# RZN2H register map
Vendor: Renesas Electronics Corporation; Series: RZN; File version: 1.00.00
CPU: other r0p0, little endian, MPU, no FPU, VTOR, 4 interrupt priority bits, 624 interrupts
Registers are 32-bit, read-write, reset 0x0 unless marked. A register's access mark holds for its fields unless they carry their own. Offsets are from the block's base; [hi:lo] are bit positions; {n}, {i} and the like mark numbered series; 'fields as' and 'values as' point back to an identical list; <NAME> marks a mode.

## SDHI0 — SD/MMC Host Interface
Base 0x92080000
Same registers: SDHI1 0x92090000
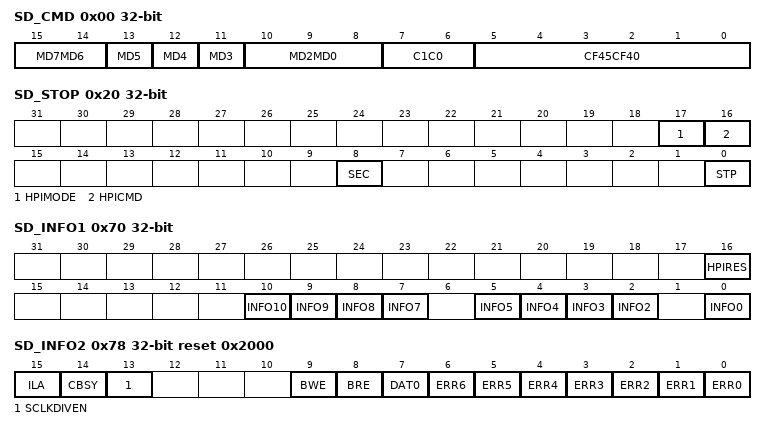
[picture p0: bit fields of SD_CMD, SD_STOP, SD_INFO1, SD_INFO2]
0x00 SD_CMD — Command Type Register
  [15:14] MD7MD6 — Multiple Block Transfer Mode (enabled at multiple block transfer)
    0=CMD12 is automatically issued at multiple block transfer; 1=CMD12 is not automatically issued at multiple block transfer; 2=Setting prohibited; 3=Setting prohibited
  [13] MD5 — Single/Multiple Block Transfer (enabled when the command with data is handled)
    0=Single block transfer; 1=Multi block transfer
  [12] MD4 — Write/Read Mode (enabled when the command with data is handled)
    0=Write (SD/MMC host interface -> SD card); 1=Read (SD/MMC host interface <- SD card)
  [11] MD3 — Data Mode (Command Type)
    0=Command without data transfer (bc, bcr, ac); 1=Command with data transfer (adtc)
  [10:8] MD2MD0 — Mode/Response Type
    0=Normal mode The response type and the transfer mode are selected by SD_CMD[7:0], and the SD_CMD[15:11] setting is disabled; 1=Setting prohibited; 2=Setting prohibited; 3=Extended mode/No response; 4=Extended mode/R1, R5, R6, or R7 response from the SD card; 5=Extended mode/R1b response from the SD card; 6=Extended mode/R2 response from the SD card; 7=Extended mode/R3 or R4 response from the SD card
  [7:6] C1C0
    0=CMD; 1=ACMD; 2=Setting prohibited
  [5:0] CF45CF40 — Command Index
0x10 SD_ARG — Command Argument Register
0x18 SD_ARG1 — Command Argument Register 1
0x20 SD_STOP — Data Stop Register
  [17] HPIMODE — HPI Mode Enable
    0=Disables HPI mode; 1=Enables HPI mode
  [16] HPICMD — HPI Command Issue
  [8] SEC — Block Count Enable
    0=Disables SD_SECCNT setting value; 1=Enables SD_SECCNT setting value
  [0] STP — Stop
0x28 SD_SECCNT — Block Count Register
  [31:0] CNT31CNT0 — Number of Transfer Blocks
0x30 SD_RSP10L ro — SD Card Response 10L Register
  [31:0] R39R8 — Hold the response from the SD card
0x38 SD_RSP1 ro — SD Card Response 1 Register
  [15:0] R39R24 — Hold the response from the SD card
0x38 SD_RSP10H ro (alternate view of SD_RSP1) — SD Card Response 10H Register
  [31:0] R71R40 — Hold the response from the SD card
0x40 SD_RSP32 ro — SD Card Response 32 Register
  [31:0] R71R40
0x48 SD_RSP3 ro — SD Card Response 3 Register
  [15:0] R71R56
0x50 SD_RSP54L ro — SD Card Response 54L Register
  [31:0] R103R72 — Hold the response from the SD card
0x58 SD_RSP5 ro — SD Card Response 5 Register
  [15:0] R103R88
0x58 SD_RSP54H ro (alternate view of SD_RSP5) — SD Card Response 54H Register
  [23:0] R127R104 — Hold the response from the SD card
0x60 SD_RSP76 ro — SD Card Response 76 Register
  [23:0] R127R104
0x68 SD_RSP7 ro — SD Card Response 7 Register
  [7:0] R127R120
0x70 SD_INFO1 (reset mask 0xFFFFFB5F) — SD Card Interrupt Flag Register 1
  [16] HPIRES — Response Reception Completion
  [10] INFO10 ro
    0=SDDAT3 is set to 0; 1=SDDAT3 is set to 1
  [9] INFO9 — SDDAT3 Card Insertion
  [8] INFO8 — SDDAT3 Card Removal
  [7] INFO7 ro — Write Protect
    0=ISDWP is set to 1; 1=ISDWP is set to 0
  [5] INFO5 ro — Indicates the ISDCD state.
    0=Indicates that Mcycle has elapsed with ISDCD held at 1; 1=Indicates that Mcycle has elapsed with ISDCD held at 0
  [4] INFO4 — ISDCD Card Insertion
  [3] INFO3 — ISDCD Card Removal
  [2] INFO2 — Access End
  [0] INFO0 — Response End
0x78 SD_INFO2 reset 0x2000 (reset mask 0xFFFFFF7F) — SD Card Interrupt Flag Register 2
  [15] ILA — Illegal Access Error
  [14] CBSY ro — Command Type Register Busy
    0=A command sequence has been completed; 1=A command sequence is being executed
  [13] SCLKDIVEN ro — When a command sequence is started by writing to SD_CMD, the CBSY bit is set to 1 and, at the same time, the SCLKDIVEN bit is set to 0. The SCLKDIVEN bit is set to 1 after 8 cycles of SDCLK have elapsed after setting of the CBSY bit to 0 due to completion of the command sequence.
    0=The SD bus (CMD, DAT) is busy. Do not attempt to write to the SD_CLK_CTRL register.; 1=The SD bus (CMD, DAT) is not busy
  [9] BWE — SD_BUF Write Enable
    0=Data cannot be written in SD_BUF0; 1=Data can be written in SD_BUF0
  [8] BRE — SD_BUF Read Enable
    0=Data cannot be read from SD_BUF0; 1=Data can be read from SD_BUF0
  [7] DAT0 ro — SDDAT0
    0=SDDAT0 is set to 0; 1=SDDAT0 is set to 1
  [6] ERR6 — Response Timeout
  [5] ERR5 — SD_BUF Illegal Read Access
  [4] ERR4 — SD_BUF Illegal Write Access
  [3] ERR3 — Data Timeout (except response timeout)
  [2] ERR2 — END Error
  [1] ERR1 — CRC Error
  [0] ERR0 — CMD Error
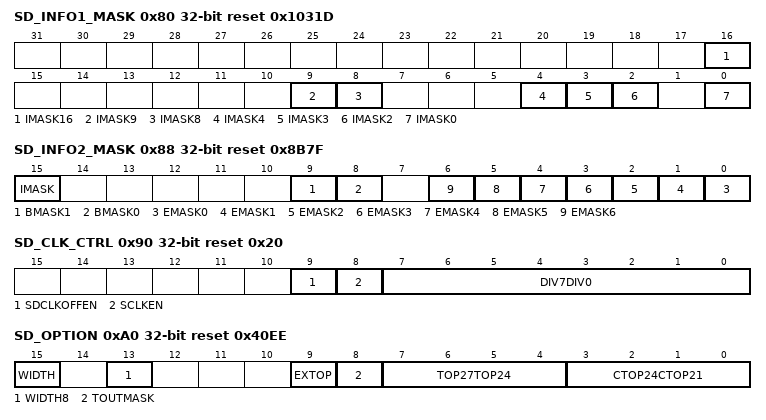
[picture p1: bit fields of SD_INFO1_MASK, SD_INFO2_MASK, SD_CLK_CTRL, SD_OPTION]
0x80 SD_INFO1_MASK reset 0x1031D — SD_INFO1 Interrupt Mask Register
  [16] IMASK16, [9] IMASK9, [8] IMASK8, [4] IMASK4, [3] IMASK3, [2] IMASK2, [0] IMASK0
0x88 SD_INFO2_MASK reset 0x8B7F — SD_INFO2 Interrupt Mask Register
  [15] IMASK, [9] BMASK1, [8] BMASK0, [n] EMASK{n} (n=0..6)
0x90 SD_CLK_CTRL reset 0x20 — SD Clock Control Register
  [9] SDCLKOFFEN — SD Clock (SDCLK) Output Automatic Control Enable
    0=Automatic control for SD clock (SDCLK) output is disabled; 1=Automatic control for SD clock (SDCLK) output is enabled
  [8] SCLKEN
    0=SD clock (SDCLK) output is disabled. The SDCLK signal is fixed 0.; 1=SD clock (SDCLK) output is enabled
  [7:0] DIV7DIV0 — SD Clock (SDCLK)
    128=PCLKAM/512; 64=PCLKAM/256; 32=PCLKAM/128; 16=PCLKAM/64; 8=PCLKAM/32; 4=PCLKAM/16; 2=PCLKAM/8; 1=PCLKAM/4; 0=PCLKAM/2; 255=PCLKAM; other=Others (Setting prohibited)
0x98 SD_SIZE reset 0x200 — Transfer Data Length Register
  [9:0] LEN9LEN0 — Transfer Data Size
0xA0 SD_OPTION reset 0x40EE — SD Card Access Control Option Register
  [15] WIDTH — Bus width
  [13] WIDTH8 — Bus width
  [9] EXTOP
    0=The TOP27TOP24[3:0] bits specify the timeout count from 210 SDCLK to 224 SDCLK; 1=The TOP27TOP24[3:0] bits specify the timeout count from 211 SDCLK to 225 SDCLK
  [8] TOUTMASK — Timeout Mask
    0=Enables timeout; 1=Disables timeout (The ERR6 and ERR3 bits in SD_INFO2 and the E6 to E0 bits in SD_ERR_STS2 are not set.)
  [7:4] TOP27TOP24
  [3:0] CTOP24CTOP21 — Card Detect Time Counter
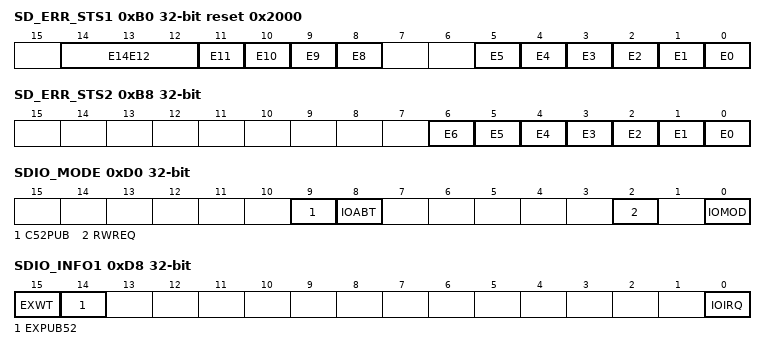
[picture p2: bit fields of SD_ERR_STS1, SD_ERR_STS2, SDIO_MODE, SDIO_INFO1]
0xB0 SD_ERR_STS1 ro reset 0x2000 — SD Error Status Register 1
  [14:12] E14E12
  [11] E11
  [10] E10
  [9] E9 — Set to 1 when a CRC error occurs in the response to a command issued within a command sequence.
  [8] E8
  [5] E5
  [4] E4
  [3] E3 — Set to 1 when an error occurs in the response length to a command issued within a command sequence.
  [2] E2
  [1] E1 — Set to 1 when an error occurs in the command index of the response to a command issued within a command sequence.
  [0] E0
0xB8 SD_ERR_STS2 ro — SD Error Status Register 2
  [6] E6
  [5] E5
  [4] E4 — Set to 1 when read data is not received even after Ncycle has elapsed after the command has been read.
  [3] E3 — Set to 1 when the interface remains in a busy state for at least Ncycle after CMD12 has been issued within a command sequence.
  [2] E2 — Set to 1 when the interface remains in a busy state for at least Ncycle after R1b response.
  [1] E1 — Set to 1 when the response to a command issued within a command sequence is not received even after 640 cycles of SDCLK have elapsed.
  [0] E0
0xC0 SD_BUF0H reset not defined — SD Buffer Read/Write H Register
0xC4 SD_BUF0L reset not defined — SD Buffer Read/Write L Register
0xD0 SDIO_MODE — SDIO Mode Control Register
  [9] C52PUB — SDIO None Abort
  [8] IOABT — SDIO Abort
  [2] RWREQ — Read Wait Request
  [0] IOMOD — SDIO Mode
    0=Disables the SD/MMC host interface to receive SDIO interrupts from the SDIO card; 1=Enables the SD/MMC host interface to receive SDIO interrupts from the SDIO card
0xD8 SDIO_INFO1 — SDIO Interrupt Flag Register
  [15] EXWT — [Setting condition]
  [14] EXPUB52 — [Setting conditions]
  [0] IOIRQ — [Setting condition]
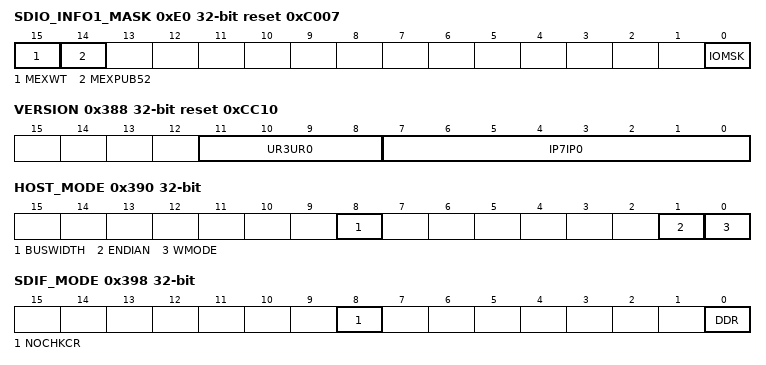
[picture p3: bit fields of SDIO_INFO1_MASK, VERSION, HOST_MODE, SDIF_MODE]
0xE0 SDIO_INFO1_MASK reset 0xC007 — SDIO_INFO1 Interrupt Mask Register
  [15] MEXWT, [14] MEXPUB52, [0] IOMSK
0x360 CC_EXT_MODE reset 0x1010 — DMA Mode Enable Register
  [1] DMASDRW — SD_BUF Read/Write DMA Transfer
    0=The SD_BUF read/write DMA transfer is disabled; 1=The SD_BUF read/write DMA transfer is enabled
0x380 SOFT_RST reset 0x7 — Software Reset Register
  [0] SDRST
    0=Reset; 1=Reset released
0x388 VERSION ro reset 0xCC10
  [11:8] UR3UR0, [7:0] IP7IP0
0x390 HOST_MODE — Host Interface Mode Setting Register
  [8] BUSWIDTH — Width for Access to SD_BUF
    0=16-bit access; 1=32-bit access
  [1] ENDIAN
  [0] WMODE — Width for Access to SD_BUF
    0=64-bit access; 1=16-bit or 32-bit access
0x398 SDIF_MODE — SD Interface Mode Setting Register
  [8] NOCHKCR — CRC Check Mask (test command for MMC supported)
    0=Enables the CRC check; 1=Disables the CRC check (the CRC16 value is ignored at read, and the CRC status is not detected at write)
  [0] DDR — DDR Mode Select
    0=Normal mode (default, high speed, or SDR); 1=DDR mode
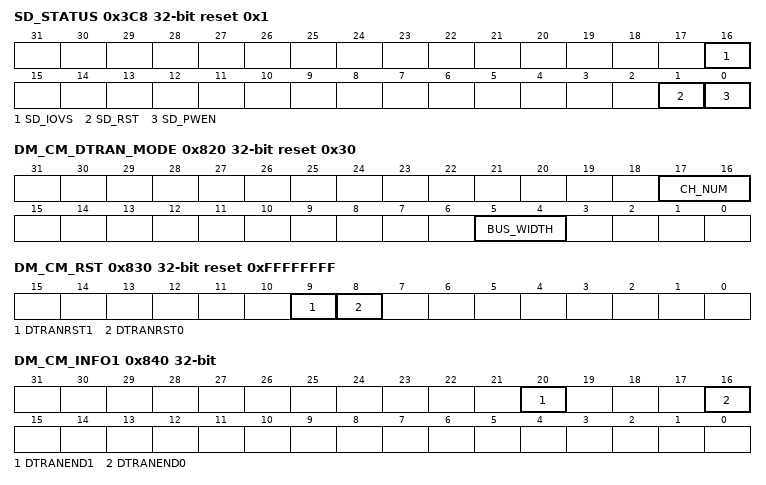
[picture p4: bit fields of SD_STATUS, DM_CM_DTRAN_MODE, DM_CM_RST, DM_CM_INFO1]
0x3C8 SD_STATUS reset 0x1
  [16] SD_IOVS
    0=The output value on the SDm_IOVS pin is 0; 1=The output value on the SDm_IOVS pin is 1
  [1] SD_RST
    0=The output value on the SD0_RST# pin is 0; 1=The output value on the SD0_RST# pin is 1
  [0] SD_PWEN
    0=The output value on the SDm_PWEN pin is 0; 1=The output value on the SDm_PWEN pin is 1
0x820 DM_CM_DTRAN_MODE reset 0x30 — DMAC Transfer Mode Register
  [17:16] CH_NUM
    0=SD downstream; 1=SD upstream; other=Others (Setting prohibited)
  [5:4] BUS_WIDTH
    3=64-bit; other=Others (Setting prohibited)
0x828 DM_CM_DTRAN_CTRL — DMAC Transfer Control Register
  [0] DM_START — DMAC Start
0x830 DM_CM_RST reset 0xFFFFFFFF — DMAC Reset Register
  [9] DTRANRST1
    0=Reset; 1=Reset released
  [8] DTRANRST0
    0=Reset; 1=Reset released
0x840 DM_CM_INFO1 — DMAC Interrupt Register 1
  [20] DTRANEND1 — DMAC Channel 1 Transfer End
  [16] DTRANEND0 — DMAC Channel 0 Transfer End
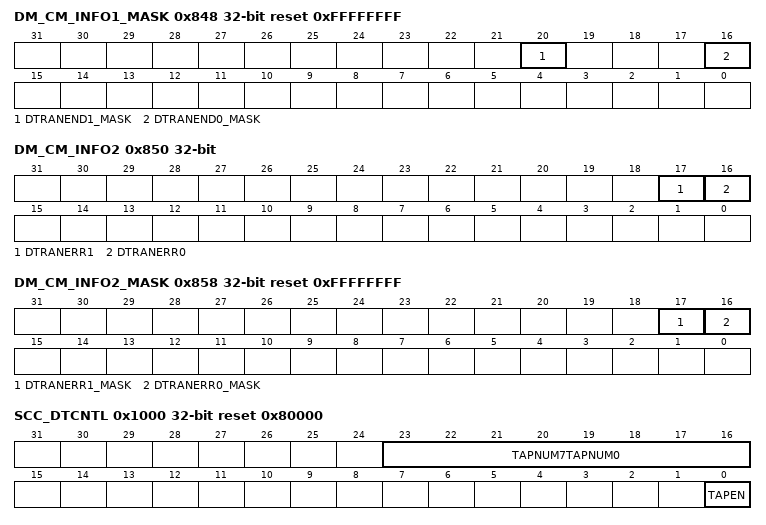
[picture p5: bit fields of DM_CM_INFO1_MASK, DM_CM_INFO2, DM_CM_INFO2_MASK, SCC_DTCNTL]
0x848 DM_CM_INFO1_MASK reset 0xFFFFFFFF — DM_CM_INFO1 Interrupt Mask Register
  [20] DTRANEND1_MASK, [16] DTRANEND0_MASK
0x850 DM_CM_INFO2 — DMAC Interrupt Register 2
  [17] DTRANERR1 — DMAC Channel 1 Error
  [16] DTRANERR0 — DMAC Channel 0 Error
0x858 DM_CM_INFO2_MASK reset 0xFFFFFFFF — DM_CM_INFO2 Interrupt Mask Register
  [17] DTRANERR1_MASK, [16] DTRANERR0_MASK
0x880 DM_DTRAN_ADDR — DMAC Transfer Address Register
  [31:3] DADDR — Destination address/Source address (8 byte unit)
0x1000 SCC_DTCNTL reset 0x80000 — Initial Setting Register
  [23:16] TAPNUM7TAPNUM0
  [0] TAPEN
    0=SCC sampling clock operation is disabled; 1=SCC sampling clock operation is enabled
0x1008 SCC_TAPSET — Sampling Clock Position Setting Register
  [7:0] TAPSET7TAPSET0 — SCC Sampling Clock Position
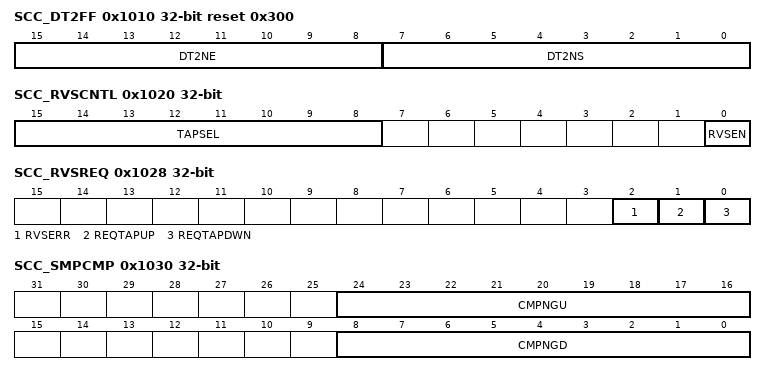
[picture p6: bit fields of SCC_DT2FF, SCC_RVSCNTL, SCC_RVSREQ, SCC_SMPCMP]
0x1010 SCC_DT2FF reset 0x300 — Hardware Adjustment Register 1
  [15:8] DT2NE — Hardware Adjustment 2
  [7:0] DT2NS — Hardware Adjustment 1
0x1018 SCC_CKSEL — Sampling Clock Selection Register
  [0] DTSEL — Sampling Clock Selection
    0=An SCC sampling clock is not used (for other than SDR104 and HS200); 1=An SCC sampling clock is used (for SDR104 or HS200)
0x1020 SCC_RVSCNTL — Sampling Clock Position Correction Register
  [15:8] TAPSEL ro — SCC Sampling Clock Position Display
  [0] RVSEN — SCC Sampling Clock Position Correction Enable
    0=SCC sampling clock position correction is disabled; 1=SCC sampling clock position correction is enabled
0x1028 SCC_RVSREQ — Sampling Clock Position Correction Request Register
  [2] RVSERR — SCC Sampling Clock Position Correction Error
    0=There is no correction error; 1=There is a correction error
  [1] REQTAPUP — SCC Sampling Clock Position Positive Direction Correction Request
    0=There is no correction request; 1=There is a correction request
  [0] REQTAPDWN — SCC Sampling Clock Position Negative Direction Correction Request
    values as REQTAPUP
0x1030 SCC_SMPCMP — Sampling Data Comparison Register
  [24:16] CMPNGU — Comparison of sampling data with the previous TAP Clock
    0=Match; 1=Mismatch
  [8:0] CMPNGD — Comparison of sampling data with the after TAP Clock
    0=Match; 1=Mismatch
0x1038 SCC_TMPPORT — Hardware Adjustment Register 2
  [15:0] TMPOUT — Hardware adjustment 3
